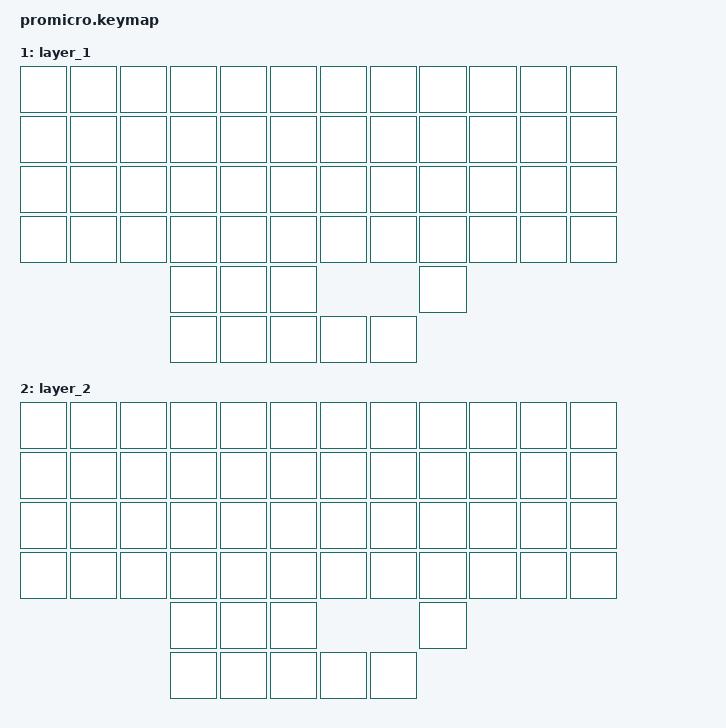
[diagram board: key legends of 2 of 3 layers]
/*
 * Copyright (c) 2020 The ZMK Contributors
 *
 * SPDX-License-Identifier: MIT
 */

#include <behaviors.dtsi>
#include <dt-bindings/zmk/keys.h>
#include <dt-bindings/zmk/bt.h>
#include <dt-bindings/zmk/outputs.h>
#include <dt-bindings/zmk/ext_power.h>
#include <dt-bindings/led/led.h>
#include <dt-bindings/zmk/rgb.h>
#include <dt-bindings/zmk/mouse.h>
#include <behaviors/mouse_keys.dtsi>

/ {
    keymap {
        compatible = "zmk,keymap";

        default_layer {
            bindings = <
&kp TAB      &kp Q        &kp W        &kp E        &kp R        &kp T        &kp Y        &kp U        &kp I        &kp O        &kp P        &kp BSPC
            &kp LCTRL    &kp A        &kp S        &kp D        &kp F        &kp G        &kp H        &kp J        &kp K        &kp L        &kp SEMI     &kp SQT
            &kp LSHFT    &kp Z        &kp X        &kp C        &kp V        &kp B        &kp N        &kp M        &kp COMMA    &kp DOT      &kp FSLH     &kp RSHFT
            &kp GRAVE    &kp LALT     &kp LGUI     &kp ESC      &kp MINUS    &kp EQUAL    &kp LBRC     &kp RBRC     &kp BSLH     &kp N0       &kp K_APP    &kp RCTRL
            &mo LOWER    &kp SPACE    &kp ENTER    &kp LEFT     &kp RIGHT    &kp DOWN     &kp UP       &kp HOME     &kp PG_DN    &kp PG_UP    &kp END      &mo RAISE
            >;

            sensor-bindings =
                <&inc_dec_kp C_VOL_UP C_VOL_DN>,
                <&inc_dec_kp A B>;
        };

        layer_1 {
            bindings = <
&none  &none  &none  &none  &none  &none    &none  &none  &none  &none  &none  &none
&none  &none  &none  &none  &none  &none    &none  &none  &none  &none  &none  &none
&none  &none  &none  &none  &none  &none    &none  &none  &none  &none  &none  &none
&none  &none  &none  &none  &none  &none    &none  &none  &none  &none  &none  &none
                     &none  &none  &none                  &none
                     &none  &none  &none    &none  &none
            >;

            sensor-bindings =   
                <&inc_dec_kp C_VOL_UP C_VOL_DN>,
                <&inc_dec_kp A B>;
        };

        layer_2 {
            bindings = <
&none  &none  &none  &none  &none  &none    &none  &none  &none  &none  &none  &none
&none  &none  &none  &none  &none  &none    &none  &none  &none  &none  &none  &none
&none  &none  &none  &none  &none  &none    &none  &none  &none  &none  &none  &none
&none  &none  &none  &none  &none  &none    &none  &none  &none  &none  &none  &none
                     &none  &none  &none                  &none
                     &none  &none  &none    &none  &none
            >;

            sensor-bindings = 
                <&inc_dec_kp C_VOL_UP C_VOL_DN>,
                <&inc_dec_kp A B>;
        };
    };
};
